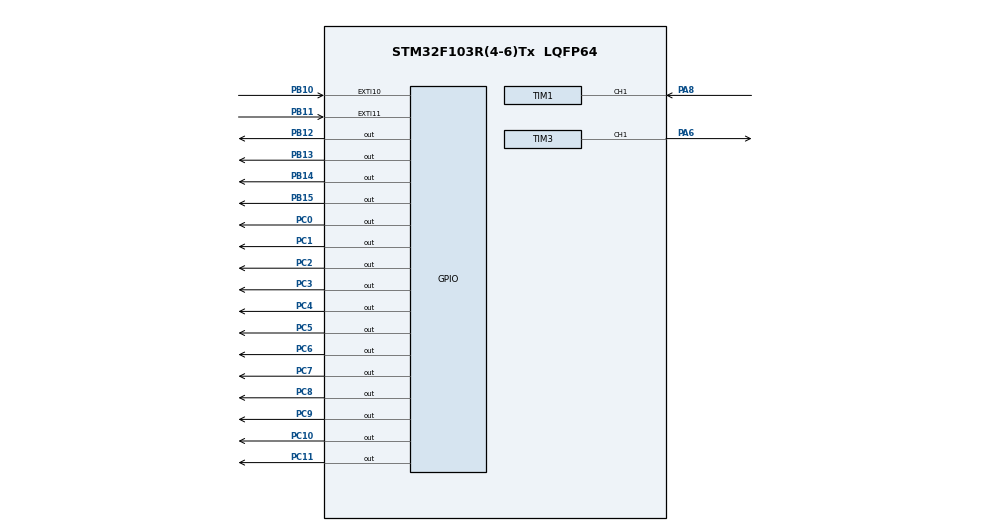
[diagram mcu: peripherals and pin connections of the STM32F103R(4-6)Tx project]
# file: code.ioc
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Mcu.Family=STM32F1
PC10.Signal=GPIO_Output
PC11.Signal=GPIO_Output
PC8.Signal=GPIO_Output
PC4.Signal=GPIO_Output
PC2.Signal=GPIO_Output
PC6.Signal=GPIO_Output
NVIC.TIM1_UP_IRQn=true\:0\:0\:false\:false\:true\:true\:true
TIM3.Pulse-Output\ Compare1\ CH1=3999
PB11.GPIO_PuPd=GPIO_NOPULL
PC0.Signal=GPIO_Output
PB11.Signal=GPXTI11
PB13.Signal=GPIO_Output
PB15.Signal=GPIO_Output
VP_SYS_VS_ND.Mode=No_Debug
ProjectManager.StackSize=0x400
TIM1.Prescaler=999
SH.S_TIM1_CH1.0=TIM1_CH1,Input_Capture1_from_TI1
ProjectManager.TargetToolchain=Makefile
TIM3.Period=15999
PC7.Signal=GPIO_Output
PC3.Signal=GPIO_Output
TIM3.Channel-Output\ Compare1\ CH1=TIM_CHANNEL_1
PB10.Signal=GPXTI10
NVIC.EXTI15_10_IRQn=true\:0\:0\:false\:false\:true\:true\:true
PB14.Signal=GPIO_Output
board=custom
NVIC.TIM3_IRQn=true\:0\:0\:false\:false\:true\:true\:true
PB13.GPIO_PuPd=GPIO_PULLUP
RCC.APB2Freq_Value=8000000
TIM3.OCMode_1=TIM_OCMODE_TOGGLE
TIM3.Prescaler=999
PA8.Signal=S_TIM1_CH1
SH.S_TIM3_CH1.0=TIM3_CH1,Output Compare1 CH1
PB10.GPIO_ModeDefaultEXTI=GPIO_MODE_IT_RISING_FALLING
Mcu.Name=STM32F103R(4-6)Tx
VP_TIM1_VS_ClockSourceINT.Mode=Internal
NVIC.TIM1_CC_IRQn=true\:0\:0\:false\:false\:true\:true\:true
Mcu.Package=LQFP64
PA6.Signal=S_TIM3_CH1
PB14.GPIO_PuPd=GPIO_PULLUP
PB15.GPIO_PuPd=GPIO_PULLUP
TIM1.Channel-Input_Capture1_from_TI1=TIM_CHANNEL_1
PB11.GPIO_ModeDefaultEXTI=GPIO_MODE_IT_FALLING
ProjectManager.HeapSize=0x200
NVIC.PriorityGroup=NVIC_PRIORITYGROUP_4
PC5.Signal=GPIO_Output
TIM1.Period=79
PC9.Signal=GPIO_Output
PB12.GPIO_PuPd=GPIO_PULLUP
RCC.APB1Freq_Value=8000000
VP_TIM3_VS_ClockSourceINT.Mode=Internal
PC1.Signal=GPIO_Output
PB12.Signal=GPIO_Output

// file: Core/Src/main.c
/* USER CODE BEGIN Header */
/**
 ******************************************************************************
 * @file           : main.c
 * @brief          : Main program body
 ******************************************************************************
 * @attention
 *
 * <h2><center>&copy; Copyright (c) 2020 STMicroelectronics.
 * All rights reserved.</center></h2>
 *
 * This software component is licensed by ST under BSD 3-Clause license,
 * the "License"; You may not use this file except in compliance with the
 * License. You may obtain a copy of the License at:
 *                        opensource.org/licenses/BSD-3-Clause
 *
 ******************************************************************************
 */
/* USER CODE END Header */
#include "main.h"
#include "tim.h"
#include "gpio.h"

/* USER CODE BEGIN Includes */
#include "casovnik.h"
/* USER CODE END Includes */

void SystemClock_Config(void);

int main(void)
{

	/* MCU Configuration--------------------------------------------------------*/

	/* Reset of all peripherals, Initializes the Flash interface and the Systick. */
	HAL_Init();

	/* Configure the system clock */
	SystemClock_Config();

	/* Initialize all configured peripherals */
	MX_GPIO_Init();
	MX_TIM1_Init();
	MX_TIM3_Init();
	/* USER CODE BEGIN 2 */

	setGPIOB(GPIO_PIN_13, 1);
	setGPIOB(GPIO_PIN_14, 1);

	casovnik();

	HAL_TIM_OC_Start_IT(&htim3, TIM_CHANNEL_1);

	/* USER CODE END 2 */

	/* Infinite loop */
	while (1)
	{

	}
}

void SystemClock_Config(void)
{
	RCC_OscInitTypeDef RCC_OscInitStruct =
	{ 0 };
	RCC_ClkInitTypeDef RCC_ClkInitStruct =
	{ 0 };

	/** Initializes the RCC Oscillators according to the specified parameters
	 * in the RCC_OscInitTypeDef structure.
	 */
	RCC_OscInitStruct.OscillatorType = RCC_OSCILLATORTYPE_HSI;
	RCC_OscInitStruct.HSIState = RCC_HSI_ON;
	RCC_OscInitStruct.HSICalibrationValue = RCC_HSICALIBRATION_DEFAULT;
	RCC_OscInitStruct.PLL.PLLState = RCC_PLL_NONE;
	if (HAL_RCC_OscConfig(&RCC_OscInitStruct) != HAL_OK)
	{
		Error_Handler();
	}
	/** Initializes the CPU, AHB and APB buses clocks
	 */
	RCC_ClkInitStruct.ClockType = RCC_CLOCKTYPE_HCLK | RCC_CLOCKTYPE_SYSCLK
			| RCC_CLOCKTYPE_PCLK1 | RCC_CLOCKTYPE_PCLK2;
	RCC_ClkInitStruct.SYSCLKSource = RCC_SYSCLKSOURCE_HSI;
	RCC_ClkInitStruct.AHBCLKDivider = RCC_SYSCLK_DIV1;
	RCC_ClkInitStruct.APB1CLKDivider = RCC_HCLK_DIV1;
	RCC_ClkInitStruct.APB2CLKDivider = RCC_HCLK_DIV1;

	if (HAL_RCC_ClockConfig(&RCC_ClkInitStruct, FLASH_LATENCY_0) != HAL_OK)
	{
		Error_Handler();
	}
}

void Error_Handler(void)
{
}

/************************ (C) COPYRIGHT STMicroelectronics *****END OF FILE****/
